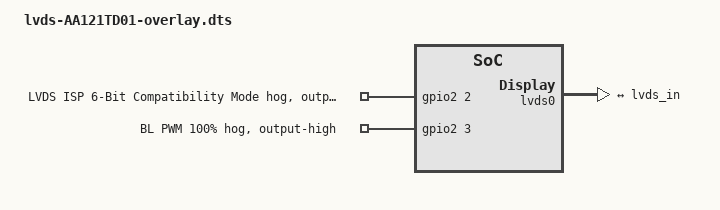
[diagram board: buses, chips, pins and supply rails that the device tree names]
/*
 * Device Tree Source for the Kingfisher (ULCB extension) LVDS panel
 *
 * Copyright (C) 2018 Renesas Electronics Corp.
 * Copyright (C) 2018 Cogent Embedded, Inc.
 * Copyright (C) 2019 GlobalLogic
 *
 * This file is licensed under the terms of the GNU General Public License
 * version 2.  This program is licensed "as is" without any warranty of any
 * kind, whether express or implied.
 */

/dts-v1/;
/plugin/;

#include <dt-bindings/gpio/gpio.h>

&lvds {
	compatible = "panel-lvds";
	width-mm = <210>;
	height-mm = <158>;
	data-mapping = "jeida-24";

	panel-timing {
		/* 1280x800 @60Hz Boundary Devices BD101LCC1 compatible panel */
		clock-frequency = <71000000>;
		hactive = <1280>;
		vactive = <800>;
		hsync-len = <40>;
		hfront-porch = <80>;
		hback-porch = <40>;
		vfront-porch = <14>;
		vback-porch = <14>;
		vsync-len = <4>;
	};
};

&gpio2 {
	mode {
		gpio-hog;
		gpios = <2 GPIO_ACTIVE_HIGH>;
		output-low;
		line-name = "LVDS ISP 6-Bit Compatibility Mode";
	};

	bl_pwm {
		gpio-hog;
		gpios = <3 GPIO_ACTIVE_HIGH>;
		output-high;
		line-name = "BL PWM 100%";
	};
};

&lvds0 {
	ports {
		port@1 {
			lvds0_out: endpoint {
				remote-endpoint = <&lvds_in>;
			};
		};
	};
};
